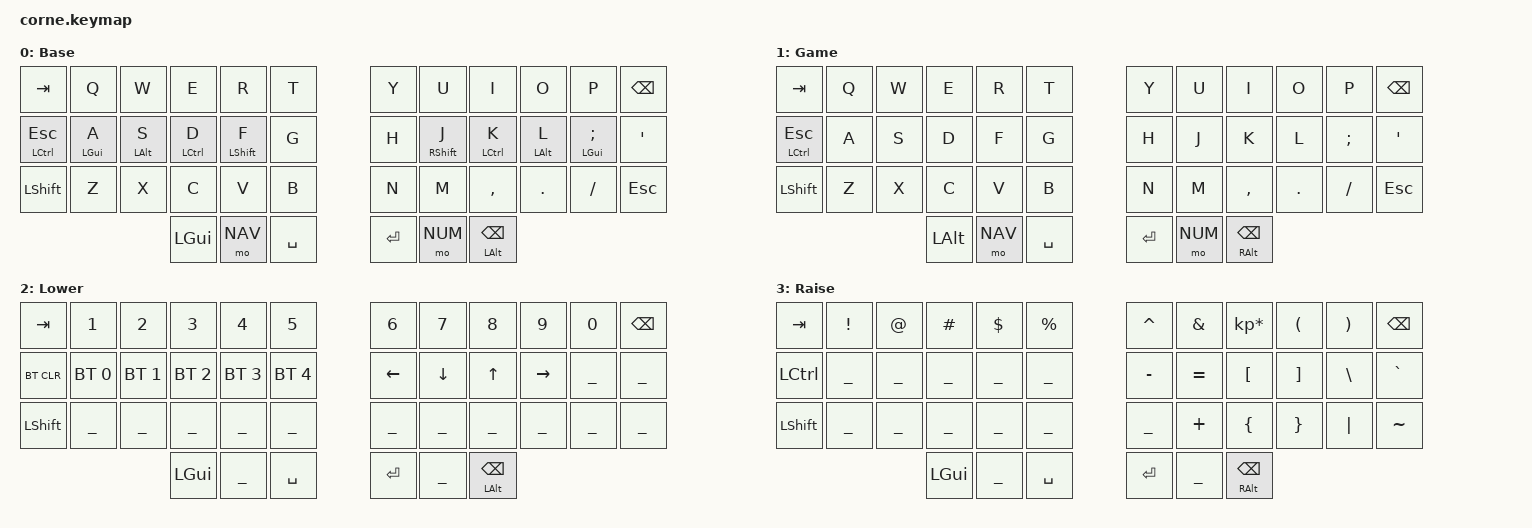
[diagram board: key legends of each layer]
#define CONFIG_WIRELESS
#include "zmk-helpers/key-labels/42.h"
#include "base.keymap"

/* Keymap */

ZMK_LAYER(Base,
    &kp TAB       &kp Q        &kp W        &kp E           &kp R        &kp T             &kp Y    &kp U          &kp I           &kp O         &kp P             &kp BSPC
    &mt LCTRL ESC &hml LGUI A  &hml LALT S  &hml LCTRL D    &hml LSHFT F &kp G             &kp H    &hmr RSHFT J   &hmr LCTRL K    &hmr LALT L   &hmr LGUI SEMI    &kp SQT
    &kp LSHFT     &kp Z        &kp X        &kp C           &kp V        &kp B             &kp N    &kp M          &kp COMMA       &kp DOT       &kp FSLH          &kp ESC
                                            &kp LGUI        &mo NAV      &kp SPACE         &kp RET  &mo NUM        &mt LALT BSPC
)
ZMK_LAYER(Game,
    &kp TAB        &kp Q  &kp W  &kp E     &kp R    &kp T        &kp Y    &kp U    &kp I          &kp O    &kp P     &kp BSPC
    &mt LCTRL ESC  &kp A  &kp S  &kp D     &kp F    &kp G        &kp H    &kp J    &kp K          &kp L    &kp SEMI  &kp SQT
    &kp LSHFT      &kp Z  &kp X  &kp C     &kp V    &kp B        &kp N    &kp M    &kp COMMA      &kp DOT  &kp FSLH  &kp ESC
                                 &kp LALT &mo NAV   &kp SPACE    &kp RET  &mo NUM  &mt RALT BSPC
)
ZMK_LAYER(Lower,
    &kp TAB     &kp N1        &kp N2        &kp N3        &kp N4        &kp N5          &kp N6    &kp N7    &kp N8         &kp N9     &kp N0  &kp BSPC
    &bt BT_CLR  &bt BT_SEL 0  &bt BT_SEL 1  &bt BT_SEL 2  &bt BT_SEL 3  &bt BT_SEL 4    &kp LEFT  &kp DOWN  &kp UP         &kp RIGHT  ___     ___
    &kp LSHFT   ___           ___           ___           ___           ___             ___       ___       ___            ___        ___     ___
                              &kp LGUI      ___           &kp SPACE     &kp RET         ___       &mt LALT BSPC
)

ZMK_LAYER(Raise,
    &kp TAB    &kp EXCL  &kp AT  &kp HASH  &kp DLLR  &kp PRCNT    &kp CARET  &kp AMPS   &kp KP_MULTIPLY  &kp LPAR  &kp RPAR  &kp BSPC
    &kp LCTRL  ___    ___  ___    ___      ___       &kp MINUS    &kp EQUAL  &kp LBKT         &kp RBKT  &kp BSLH  &kp GRAVE
    &kp LSHFT  ___    ___  ___    ___      ___       &kp UNDER    &kp PLUS   &kp LBRC         &kp RBRC  &kp PIPE  &kp TILDE
                                 &kp LGUI  ___       &kp SPACE    &kp RET    ___     &mt RALT BSPC
)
